VERSION ""

NS_ :

BS_:

BU_: CH110

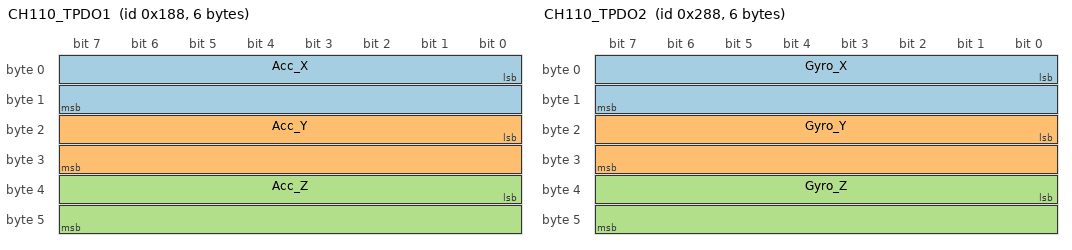
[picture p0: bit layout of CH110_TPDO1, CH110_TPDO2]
BO_ 392 CH110_TPDO1: 6 CH110
 SG_ Acc_X : 0|16@1- (0.001,0) [-8|8] "g" Vector__XXX
 SG_ Acc_Y : 16|16@1- (0.001,0) [-8|8] "g" Vector__XXX
 SG_ Acc_Z : 32|16@1- (0.001,0) [-8|8] "g" Vector__XXX

BO_ 648 CH110_TPDO2: 6 CH110
 SG_ Gyro_X : 0|16@1- (0.1,0) [-500|500] "deg/s" Vector__XXX
 SG_ Gyro_Y : 16|16@1- (0.1,0) [-500|500] "deg/s" Vector__XXX
 SG_ Gyro_Z : 32|16@1- (0.1,0) [-500|500] "deg/s" Vector__XXX

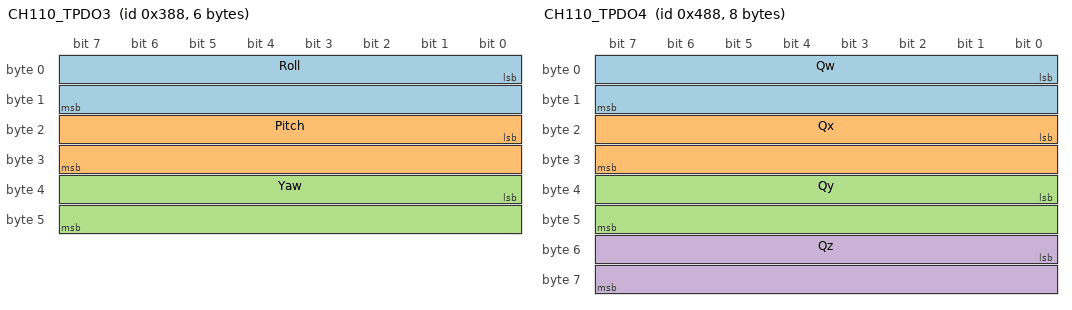
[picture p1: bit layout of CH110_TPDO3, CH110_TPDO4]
BO_ 904 CH110_TPDO3: 6 CH110
 SG_ Roll : 0|16@1- (0.01,0) [-180|180] "deg" Vector__XXX
 SG_ Pitch : 16|16@1- (0.01,0) [-90|90] "deg" Vector__XXX
 SG_ Yaw : 32|16@1- (0.01,0) [-180|180] "deg" Vector__XXX

BO_ 1160 CH110_TPDO4: 8 CH110
 SG_ Qw : 0|16@1- (0.0001,0) [-1|1] "" Vector__XXX
 SG_ Qx : 16|16@1- (0.0001,0) [-1|1] "" Vector__XXX
 SG_ Qy : 32|16@1- (0.0001,0) [-1|1] "" Vector__XXX
 SG_ Qz : 48|16@1- (0.0001,0) [-1|1] "" Vector__XXX

BO_ 1672 CH110_TPDO5: 4 CH110
